VERSION ""

NS_ :

BS_:

BU_:

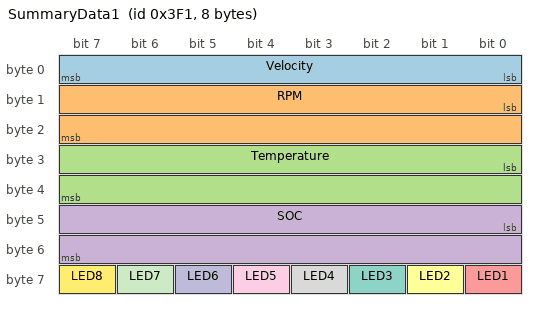
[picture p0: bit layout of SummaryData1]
BO_ 1009 SummaryData1: 8 Vector__XXX
 SG_ Velocity : 0|8@1+ (1,0) [0|0] "km/hr" Vector__XXX
 SG_ RPM : 8|16@1+ (1,0) [0|0] "rpm" Vector__XXX
 SG_ Temperature : 24|16@1- (0.1,-40) [0|0] "°C" Vector__XXX
 SG_ SOC : 40|16@1+ (0.1,-50) [0|0] "%" Vector__XXX
 SG_ LED1 : 56|1@1+ (1,0) [0|0] "" Vector__XXX
 SG_ LED2 : 57|1@1+ (1,0) [0|0] "" Vector__XXX
 SG_ LED3 : 58|1@1+ (1,0) [0|0] "" Vector__XXX
 SG_ LED4 : 59|1@1+ (1,0) [0|0] "" Vector__XXX
 SG_ LED5 : 60|1@1+ (1,0) [0|0] "" Vector__XXX
 SG_ LED6 : 61|1@1+ (1,0) [0|0] "" Vector__XXX
 SG_ LED7 : 62|1@1+ (1,0) [0|0] "" Vector__XXX
 SG_ LED8 : 63|1@1+ (1,0) [0|0] "" Vector__XXX
